AUTOSAR XML (schema 4-2-2)
package /ASW_COM_SWC
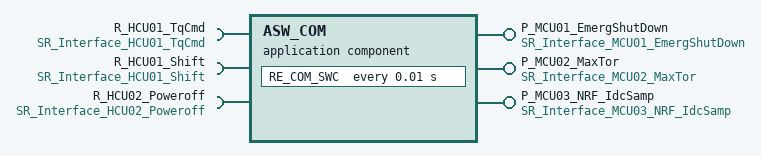
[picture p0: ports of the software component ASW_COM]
  application sw component type ASW_COM
    provide port P_MCU01_EmergShutDown: provided-interface=SR_Interface_MCU01_EmergShutDown
    provide port P_MCU02_MaxTor: provided-interface=SR_Interface_MCU02_MaxTor
    provide port P_MCU03_NRF_IdcSamp: provided-interface=SR_Interface_MCU03_NRF_IdcSamp
    require port R_HCU01_TqCmd: required-interface=SR_Interface_HCU01_TqCmd
    require port R_HCU01_Shift: required-interface=SR_Interface_HCU01_Shift
    require port R_HCU02_Poweroff: nonqueued-receiver-com-spec{data-element=HCU02_Poweroff, alive-timeout=0.3}, required-interface=SR_Interface_HCU02_Poweroff
    behavior IB_ASW_COM
      timing event TE_RE_COM_SWC_10ms: start-on-event=RE_COM_SWC, period=0.01
      data receive error event DREE_R_HCU02_Poweroff_Timeout: start-on-event=RE_COM_SWC, data=R_HCU02_Poweroff.HCU02_Poweroff
      runnable RE_COM_SWC
        data-read-accesses:
          access VA_READ_HCU01_TqCmd: accessed-variable=R_HCU01_TqCmd.HCU01_TqCmd
          access VA_READ_HCU01_Shift: accessed-variable=R_HCU01_Shift.HCU01_Shift
          access VA_READ_HCU02_Poweroff: accessed-variable=R_HCU02_Poweroff.HCU02_Poweroff
        data-write-accesses:
          access VA_WRITE_MCU01_EmergShutDown: accessed-variable=P_MCU01_EmergShutDown.MCU01_EmergShutDown
          access VA_WRITE_MCU02_MaxTor: accessed-variable=P_MCU02_MaxTor.MCU02_MaxTor
          access VA_WRITE_MCU03_NRF_IdcSamp: accessed-variable=P_MCU03_NRF_IdcSamp.MCU03_NRF_IdcSamp
package /COM_Interface
  6 x sender receiver interface:
    SR_Interface_MCU01_EmergShutDown
      data MCU01_EmergShutDown: type=Idt_Boolean
    SR_Interface_MCU02_MaxTor
      data MCU02_MaxTor: type=Idt_Float
    SR_Interface_MCU03_NRF_IdcSamp
      data MCU03_NRF_IdcSamp: type=Idt_Float
    SR_Interface_HCU02_Poweroff
      data HCU02_Poweroff: type=Idt_Boolean
    SR_Interface_HCU01_Shift
      data HCU01_Shift: type=Idt_Uint8
    SR_Interface_HCU01_TqCmd
      data HCU01_TqCmd: type=Idt_Float
package /DataTypes/ImplementationDataTypes
  impl type Idt_Boolean: category=VALUE
  impl type Idt_Float: category=VALUE
  impl type Idt_Uint8: category=VALUE
